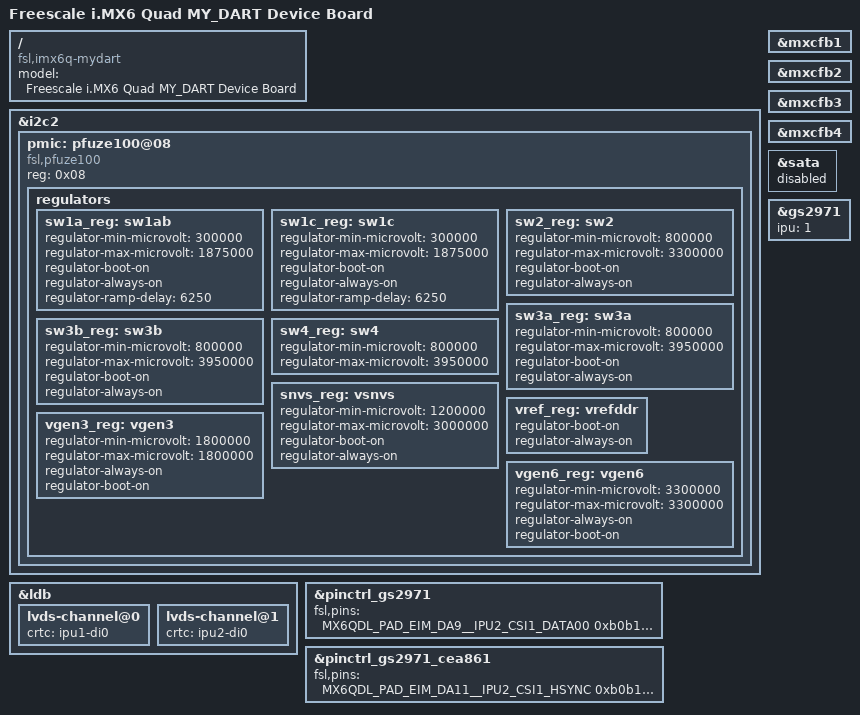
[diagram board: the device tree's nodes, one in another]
/*
 * Copyright (C) 2014 Variscite, Ltd. All Rights Reserved
 * Donio Ron: ron.d@variscite.com
 *
 * Copyright 2012 Freescale Semiconductor, Inc.
 * Copyright 2011 Linaro Ltd.
 *
 * The code contained herein is licensed under the GNU General Public
 * License. You may obtain a copy of the GNU General Public License
 * Version 2 or later at the following locations:
 *
 * http://www.opensource.org/licenses/gpl-license.html
 * http://www.gnu.org/copyleft/gpl.html
 */

/dts-v1/;

#define VAR_DART_MX6

#include "imx6q.dtsi"
#include "imx6qdl-mydart.dtsi"

/ {
	model = "Freescale i.MX6 Quad MY_DART Device Board";
	compatible = "fsl,imx6q-mydart", "fsl,imx6q";
};

&i2c2 {
	pmic: pfuze100@08 {
		compatible = "fsl,pfuze100";
		reg = <0x08>;

		regulators {
			sw1a_reg: sw1ab {
				regulator-min-microvolt = <300000>;
				regulator-max-microvolt = <1875000>;
				regulator-boot-on;
				regulator-always-on;
				regulator-ramp-delay = <6250>;
			};

			sw1c_reg: sw1c {
				regulator-min-microvolt = <300000>;
				regulator-max-microvolt = <1875000>;
				regulator-boot-on;
				regulator-always-on;
				regulator-ramp-delay = <6250>;
			};

			sw2_reg: sw2 {
				regulator-min-microvolt = <800000>;
				regulator-max-microvolt = <3300000>;
				regulator-boot-on;
				regulator-always-on;
			};

			sw3a_reg: sw3a {
				regulator-min-microvolt = <800000>;
				regulator-max-microvolt = <3950000>;
				regulator-boot-on;
				regulator-always-on;
			};

			sw3b_reg: sw3b {
				regulator-min-microvolt = <800000>;
				regulator-max-microvolt = <3950000>;
				regulator-boot-on;
				regulator-always-on;
			};

			sw4_reg: sw4 {
				regulator-min-microvolt = <800000>;
				regulator-max-microvolt = <3950000>;
			};

			snvs_reg: vsnvs {
				regulator-min-microvolt = <1200000>;
				regulator-max-microvolt = <3000000>;
				regulator-boot-on;
				regulator-always-on;
			};

			vref_reg: vrefddr {
				regulator-boot-on;
				regulator-always-on;
			};

#if 0
//Not used in Dart
			vgen1_reg: vgen1 {
				regulator-min-microvolt = <800000>;
				regulator-max-microvolt = <1550000>;
			};

			vgen2_reg: vgen2 {
				regulator-min-microvolt = <800000>;
				regulator-max-microvolt = <1550000>;
			};

			vgen4_reg: vgen4 {
				regulator-min-microvolt = <1800000>;
				regulator-max-microvolt = <3300000>;
				regulator-always-on;
				regulator-boot-on;
			};

			vgen5_reg: vgen5 {
				regulator-min-microvolt = <1800000>;
				regulator-max-microvolt = <3300000>;
				regulator-always-on;
				regulator-boot-on;
			};
#endif
			vgen3_reg: vgen3 {
				regulator-min-microvolt = <1800000>;
				regulator-max-microvolt = <1800000>;
				regulator-always-on;
				regulator-boot-on;
			};

			vgen6_reg: vgen6 {
				regulator-min-microvolt = <3300000>;
				regulator-max-microvolt = <3300000>;
				regulator-always-on;
				regulator-boot-on;
			};
		};
	};
};

&ldb {
	lvds-channel@0 {
		crtc = "ipu1-di0";
	};

	lvds-channel@1 {
		crtc = "ipu2-di0";
	};
};

&mxcfb1 {
	status = "okay";
};

&mxcfb2 {
	status = "okay";
};

&mxcfb3 {
	status = "okay";
};

&mxcfb4 {
	status = "okay";
};

&sata {
	status = "disabled";
};

&gs2971 {
	ipu = <1>;
};

&pinctrl_gs2971 { /* parallel camera */
	fsl,pins = <
		MX6QDL_PAD_EIM_DA9__IPU2_CSI1_DATA00	0xb0b1
		MX6QDL_PAD_EIM_DA8__IPU2_CSI1_DATA01	0xb0b1
		MX6QDL_PAD_EIM_DA7__IPU2_CSI1_DATA02	0xb0b1
		MX6QDL_PAD_EIM_DA6__IPU2_CSI1_DATA03	0xb0b1
		MX6QDL_PAD_EIM_DA5__IPU2_CSI1_DATA04	0xb0b1
		MX6QDL_PAD_EIM_DA4__IPU2_CSI1_DATA05	0xb0b1
		MX6QDL_PAD_EIM_DA3__IPU2_CSI1_DATA06	0xb0b1
		MX6QDL_PAD_EIM_DA2__IPU2_CSI1_DATA07	0xb0b1
		MX6QDL_PAD_EIM_DA1__IPU2_CSI1_DATA08	0xb0b1
		MX6QDL_PAD_EIM_DA0__IPU2_CSI1_DATA09	0xb0b1
		MX6QDL_PAD_EIM_EB1__IPU2_CSI1_DATA10	0xb0b1
		MX6QDL_PAD_EIM_EB0__IPU2_CSI1_DATA11	0xb0b1
		MX6QDL_PAD_EIM_A17__IPU2_CSI1_DATA12	0xb0b1
		MX6QDL_PAD_EIM_A18__IPU2_CSI1_DATA13	0xb0b1
		MX6QDL_PAD_EIM_A19__IPU2_CSI1_DATA14	0xb0b1
		MX6QDL_PAD_EIM_A20__IPU2_CSI1_DATA15	0xb0b1
		MX6QDL_PAD_EIM_A21__IPU2_CSI1_DATA16	0xb0b1
		MX6QDL_PAD_EIM_A22__IPU2_CSI1_DATA17	0xb0b1
		MX6QDL_PAD_EIM_A23__IPU2_CSI1_DATA18	0xb0b1
		MX6QDL_PAD_EIM_A24__IPU2_CSI1_DATA19	0xb0b1
		MX6QDL_PAD_EIM_A16__IPU2_CSI1_PIXCLK	0xb0b1
		MX6QDL_PAD_EIM_DA10__GPIO3_IO10		0xb0b0	/* DATA_EN not used */
	>;
};

&pinctrl_gs2971_cea861 { /* parallel camera */
	fsl,pins = <
		MX6QDL_PAD_EIM_DA11__IPU2_CSI1_HSYNC	0xb0b1
		MX6QDL_PAD_EIM_DA12__IPU2_CSI1_VSYNC	0xb0b1
	>;
};

#if 0
&v4l2_cap_0 {
	ipu_id = <1>;
};

&ov5640_mipi {
	ipu_id = <1>;
	csi_id = <0>;
 	mipi_camera = <1>;
};

/* ov5640_mipi, tc358743_mipi */
&v4l2_cap_1 {
	ipu_id = <1>;
	csi_id = <0>;
	mipi_camera = <1>;
};
#endif

